# N32H7xx register map
Vendor: Nationstech Ltd.; File version: 1.0
CPU: CM7 r1p1, little endian, MPU, FPU, 4 interrupt priority bits
Registers are 32-bit, read-write, reset 0x0 unless marked. A register's access mark holds for its fields unless they carry their own. Offsets are from the block's base; [hi:lo] are bit positions; {n}, {i} and the like mark numbered series.

## LCDC
Base 0x5004A000
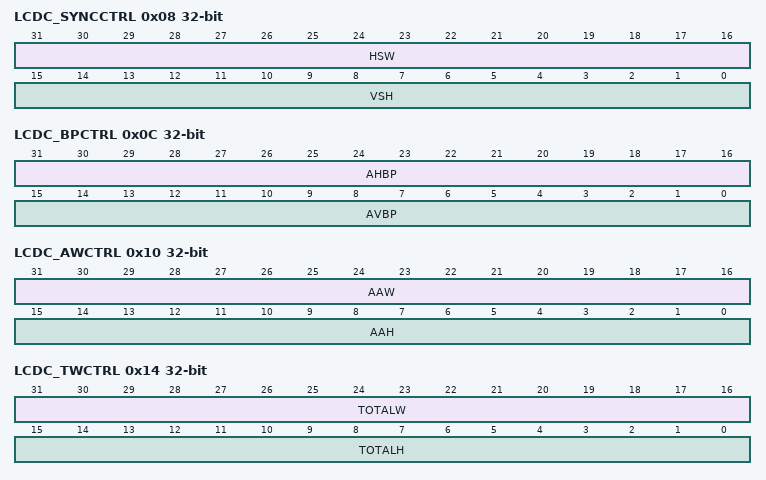
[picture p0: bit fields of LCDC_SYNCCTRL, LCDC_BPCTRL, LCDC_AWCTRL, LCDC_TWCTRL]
0x08 LCDC_SYNCCTRL
  [31:16] HSW, [15:0] VSH
0x0C LCDC_BPCTRL
  [31:16] AHBP, [15:0] AVBP
0x10 LCDC_AWCTRL
  [31:16] AAW, [15:0] AAH
0x14 LCDC_TWCTRL
  [31:16] TOTALW, [15:0] TOTALH
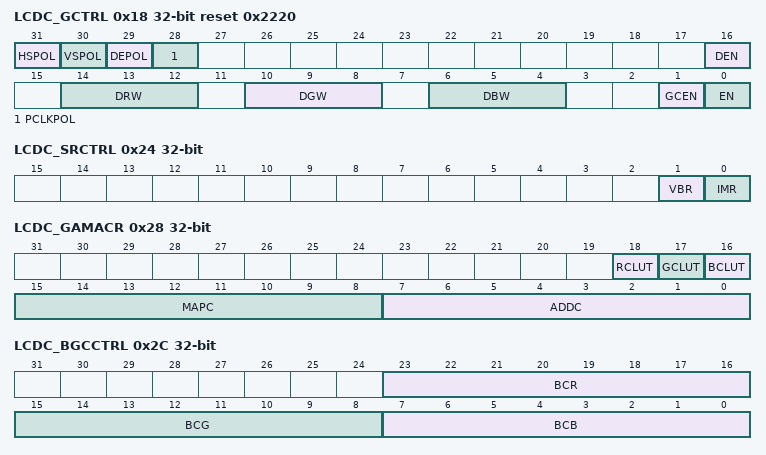
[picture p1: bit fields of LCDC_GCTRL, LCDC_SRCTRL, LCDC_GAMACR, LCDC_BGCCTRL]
0x18 LCDC_GCTRL reset 0x2220
  [31] HSPOL, [30] VSPOL, [29] DEPOL, [28] PCLKPOL, [16] DEN, [14:12] DRW ro, [10:8] DGW ro, [6:4] DBW ro, [1] GCEN, [0] EN
0x24 LCDC_SRCTRL
  [1] VBR, [0] IMR
0x28 LCDC_GAMACR wo
  [18] RCLUT, [17] GCLUT, [16] BCLUT, [15:8] MAPC, [7:0] ADDC
0x2C LCDC_BGCCTRL — LCDC_BCCTRL
  [23:16] BCR, [15:8] BCG, [7:0] BCB
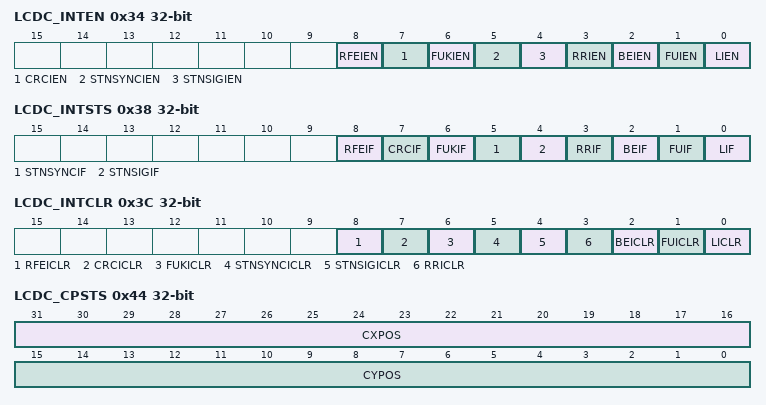
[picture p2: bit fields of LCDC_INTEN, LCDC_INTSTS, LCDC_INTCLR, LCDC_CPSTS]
0x34 LCDC_INTEN
  [8] RFEIEN, [7] CRCIEN, [6] FUKIEN, [5] STNSYNCIEN, [4] STNSIGIEN, [3] RRIEN, [2] BEIEN, [1] FUIEN, [0] LIEN
0x38 LCDC_INTSTS ro
  [8] RFEIF, [7] CRCIF, [6] FUKIF, [5] STNSYNCIF, [4] STNSIGIF, [3] RRIF, [2] BEIF, [1] FUIF, [0] LIF
0x3C LCDC_INTCLR wo
  [8] RFEICLR, [7] CRCICLR, [6] FUKICLR, [5] STNSYNCICLR, [4] STNSIGICLR, [3] RRICLR, [2] BEICLR, [1] FUICLR, [0] LICLR
0x40 LCDC_LINTPCTRL
  [15:0] LINTP
0x44 LCDC_CPSTS ro
  [31:16] CXPOS, [15:0] CYPOS
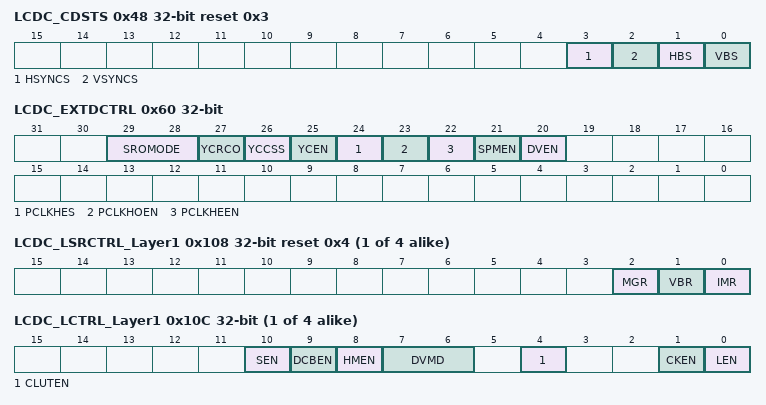
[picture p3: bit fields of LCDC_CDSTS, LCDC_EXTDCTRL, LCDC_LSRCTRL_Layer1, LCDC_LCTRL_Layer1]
0x48 LCDC_CDSTS ro reset 0x3
  [3] HSYNCS, [2] VSYNCS, [1] HBS, [0] VBS
0x60 LCDC_EXTDCTRL
  [29:28] SROMODE, [27] YCRCO, [26] YCCSS, [25] YCEN, [24] PCLKHES, [23] PCLKHOEN, [22] PCLKHEEN, [21] SPMEN, [20] DVEN
{0x8+0x100*i} LCDC_LSRCTRL_Layer{i} reset 0x4 (i=1..4) — LCDC_LSRCTRL
  [2] MGR, [1] VBR, [0] IMR wo
{0xC+0x100*i} LCDC_LCTRL_Layer{i} (i=1..4) — LCDC_LCTRL
  [10] SEN, [9] DCBEN, [8] HMEN, [7:6] DVMD, [4] CLUTEN, [1] CKEN, [0] LEN
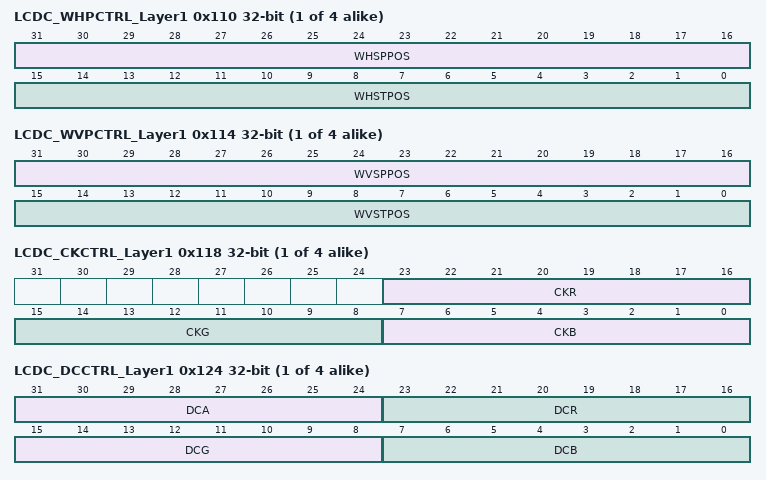
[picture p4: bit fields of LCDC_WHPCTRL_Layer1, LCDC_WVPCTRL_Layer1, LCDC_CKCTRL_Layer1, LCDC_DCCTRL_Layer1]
{0x10+0x100*i} LCDC_WHPCTRL_Layer{i} (i=1..4) — LCDC_WHPCTRL
  [31:16] WHSPPOS, [15:0] WHSTPOS
{0x14+0x100*i} LCDC_WVPCTRL_Layer{i} (i=1..4) — LCDC_WVPCTRL
  [31:16] WVSPPOS, [15:0] WVSTPOS
{0x18+0x100*i} LCDC_CKCTRL_Layer{i} (i=1..4) — LCDC_CKCTRL
  [23:16] CKR, [15:8] CKG, [7:0] CKB
{0x1C+0x100*i} LCDC_PFCTRL_Layer{i} (i=1..4) — LCDC_PFCTRL
  [2:0] PF
{0x20+0x100*i} LCDC_CACTRL_Layer{i} reset 0xFF (i=1..4) — LCDC_CACTRL
  [7:0] CA
{0x24+0x100*i} LCDC_DCCTRL_Layer{i} (i=1..4) — LCDC_DCCTRL
  [31:24] DCA, [23:16] DCR, [15:8] DCG, [7:0] DCB
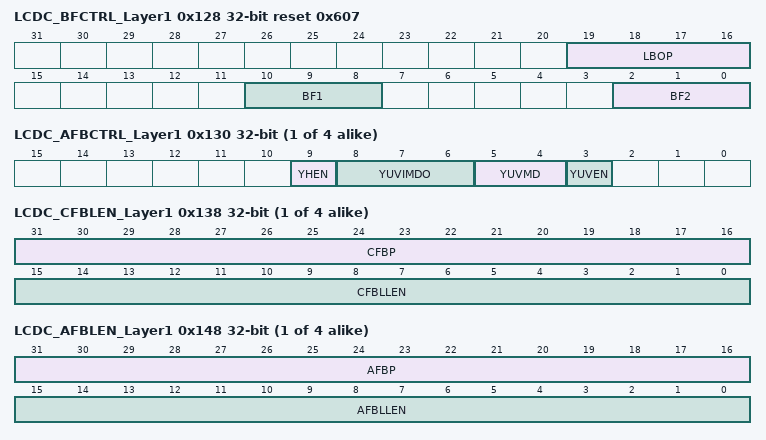
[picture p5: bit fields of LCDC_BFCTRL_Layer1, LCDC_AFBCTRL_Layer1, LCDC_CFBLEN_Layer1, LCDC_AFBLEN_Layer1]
0x128 LCDC_BFCTRL_Layer1 reset 0x607 — LCDC_BFCTRL
  [19:16] LBOP, [10:8] BF1, [2:0] BF2
{0x30+0x100*i} LCDC_AFBCTRL_Layer{i} (i=1..4) — LCDC_AFBCTRL
  [9] YHEN, [8:6] YUVIMDO, [5:4] YUVMD, [3] YUVEN
{0x34+0x100*i} LCDC_CFBADDR_Layer{i} (i=1..4) — LCDC_CFBADDR
  [31:0] CFBADDR
{0x38+0x100*i} LCDC_CFBLEN_Layer{i} (i=1..4) — LCDC_CFBLEN
  [31:16] CFBP, [15:0] CFBLLEN
{0x3C+0x100*i} LCDC_CFBLNUM_Layer{i} (i=1..4) — LCDC_CFBLNUM
  [15:0] CFBLNUM
{0x40+0x100*i} LCDC_AFBADDR0_Layer{i} (i=1..4) — LCDC_AFBADDR0
  [31:0] AFBADDR0
{0x44+0x100*i} LCDC_AFBADDR1_Layer{i} (i=1..4) — LCDC_AFBADDR1
  [31:0] AFBADDR1
{0x48+0x100*i} LCDC_AFBLEN_Layer{i} (i=1..4) — LCDC_AFBLEN
  [31:16] AFBP, [15:0] AFBLLEN
{0x4C+0x100*i} LCDC_AFBLNUM_Layer{i} (i=1..4) — LCDC_AFBLNUM
  [15:0] AFBLNUM
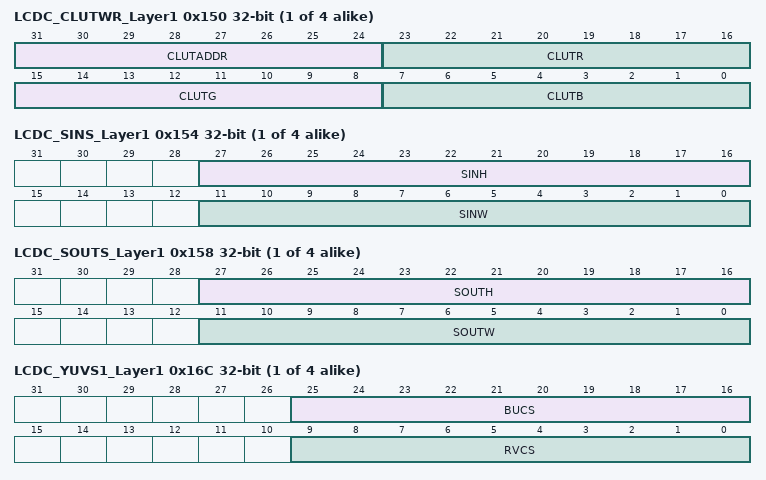
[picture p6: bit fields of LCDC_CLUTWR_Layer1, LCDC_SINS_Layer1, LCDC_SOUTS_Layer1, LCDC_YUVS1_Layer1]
{0x50+0x100*i} LCDC_CLUTWR_Layer{i} (i=1..4) — LCDC_CLUTWR
  [31:24] CLUTADDR, [23:16] CLUTR, [15:8] CLUTG, [7:0] CLUTB
{0x54+0x100*i} LCDC_SINS_Layer{i} (i=1..4) — LCDC_SINS
  [27:16] SINH, [11:0] SINW
{0x58+0x100*i} LCDC_SOUTS_Layer{i} (i=1..4) — LCDC_SOUTS
  [27:16] SOUTH, [11:0] SOUTW
{0x5C+0x100*i} LCDC_VSF_Layer{i} (i=1..4) — LCDC_VSF
  [15:0] VSF
{0x60+0x100*i} LCDC_VSP_Layer{i} (i=1..4) — LCDC_VSP
  [15:0] VSP
{0x64+0x100*i} LCDC_HSF_Layer{i} (i=1..4) — LCDC_HSF
  [15:0] HSF
{0x68+0x100*i} LCDC_HSP_Layer{i} (i=1..4) — LCDC_HSP
  [15:0] HSP
{0x6C+0x100*i} LCDC_YUVS1_Layer{i} (i=1..4) — LCDC_YUVS1
  [25:16] BUCS, [9:0] RVCS
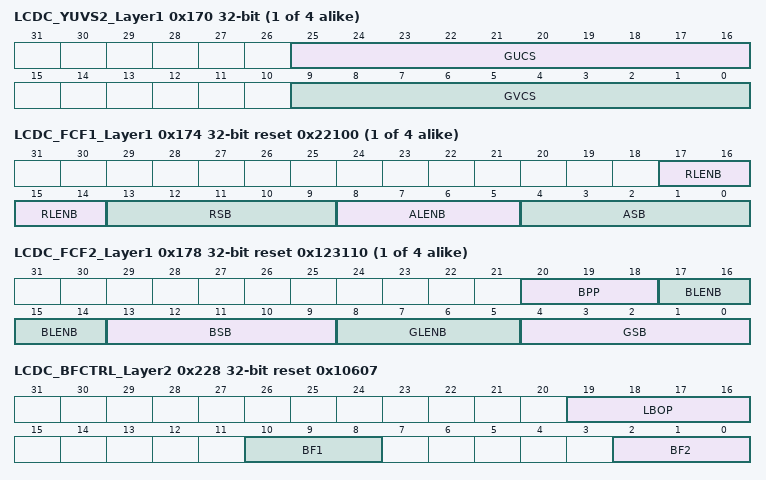
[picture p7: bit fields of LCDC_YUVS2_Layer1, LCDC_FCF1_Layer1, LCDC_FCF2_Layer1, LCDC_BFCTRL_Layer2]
{0x70+0x100*i} LCDC_YUVS2_Layer{i} (i=1..4) — LCDC_YUVS2
  [25:16] GUCS, [9:0] GVCS
{0x74+0x100*i} LCDC_FCF1_Layer{i} reset 0x22100 (i=1..4) — LCDC_FCF1
  [17:14] RLENB, [13:9] RSB, [8:5] ALENB, [4:0] ASB
{0x78+0x100*i} LCDC_FCF2_Layer{i} reset 0x123110 (i=1..4) — LCDC_FCF2
  [20:18] BPP, [17:14] BLENB, [13:9] BSB, [8:5] GLENB, [4:0] GSB
0x228 LCDC_BFCTRL_Layer2 reset 0x10607 — LCDC_BFCTRL
  [19:16] LBOP, [10:8] BF1, [2:0] BF2
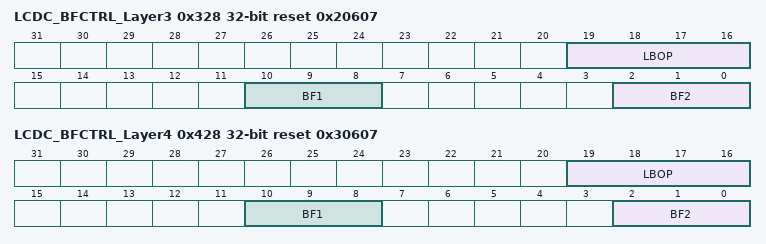
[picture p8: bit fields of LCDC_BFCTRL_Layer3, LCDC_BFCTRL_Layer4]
0x328 LCDC_BFCTRL_Layer3 reset 0x20607 — LCDC_BFCTRL
  [19:16] LBOP, [10:8] BF1, [2:0] BF2
0x428 LCDC_BFCTRL_Layer4 reset 0x30607 — LCDC_BFCTRL
  [19:16] LBOP, [10:8] BF1, [2:0] BF2
